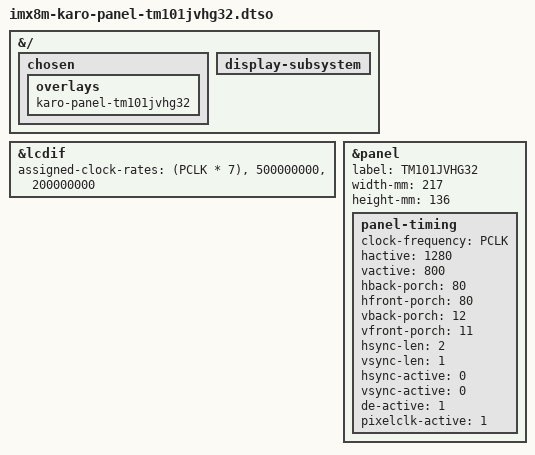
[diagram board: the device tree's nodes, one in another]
// SPDX-License-Identifier: (GPL-2.0 OR MIT)
/*
 * Copyright 2022 Lothar Waßmann <LW@KARO-electronics.de>
 *
 */

/dts-v1/;
/plugin/;

&{/} {
	chosen {
		overlays {
			karo-panel-tm101jvhg32;
		};
	};

	display-subsystem {
		status = "okay";
	};
};

#define PCLK 68200000

&lcdif {
	assigned-clock-rates = <(PCLK * 7)>, <500000000>, <200000000>;
	status = "okay";
};

&panel {
	label = "TM101JVHG32";
	width-mm = <217>;
	height-mm = <136>;
	status = "okay";

	panel-timing {
		clock-frequency = <PCLK>;
		hactive = <1280>;
		vactive = <800>;
		hback-porch = <80>;
		hfront-porch = <80>;
		vback-porch = <12>;
		vfront-porch = <11>;
		hsync-len = <2>;
		vsync-len = <1>;
		hsync-active = <0>;
		vsync-active = <0>;
		de-active = <1>;
		pixelclk-active = <1>;
	};
};
